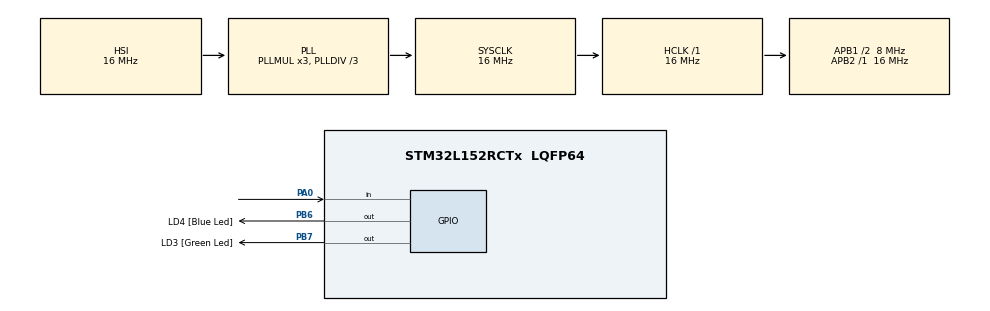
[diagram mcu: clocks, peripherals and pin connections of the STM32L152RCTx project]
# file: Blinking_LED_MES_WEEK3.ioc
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Mcu.Family=STM32L1
Mcu.Name=STM32L152RCTx
Mcu.Package=LQFP64
NVIC.PriorityGroup=NVIC_PRIORITYGROUP_0
PA0-WKUP1.GPIO_PuPd=GPIO_PULLDOWN
PA0-WKUP1.Signal=GPIO_Input
PB6.GPIO_Label=LD4 [Blue Led]
PB6.GPIO_ModeDefaultOutputPP=GPIO_MODE_OUTPUT_PP
PB6.GPIO_PuPd=GPIO_NOPULL
PB6.GPIO_Speed=GPIO_SPEED_FREQ_LOW
PB6.Signal=GPIO_Output
PB7.GPIO_Label=LD3 [Green Led]
PB7.GPIO_ModeDefaultOutputPP=GPIO_MODE_OUTPUT_PP
PB7.GPIO_PuPd=GPIO_PULLDOWN
PB7.GPIO_Speed=GPIO_SPEED_FREQ_LOW
PB7.Signal=GPIO_Output
ProjectManager.HeapSize=0x200
ProjectManager.StackSize=0x400
ProjectManager.TargetToolchain=STM32CubeIDE
RCC.48MHZClocksFreq_Value=24000000
RCC.AHBFreq_Value=16000000
RCC.APB1CLKDivider=RCC_HCLK_DIV2
RCC.APB1Freq_Value=8000000
RCC.APB1TimFreq_Value=16000000
RCC.APB2Freq_Value=16000000
RCC.APB2TimFreq_Value=16000000
RCC.HCLKFreq_Value=16000000
RCC.HSE_VALUE=8000000
RCC.HSI_VALUE=16000000
RCC.LSE_VALUE=32768
RCC.MSI_VALUE=2097000
RCC.PLLDIV=RCC_PLL_DIV3
RCC.RTCClockSelection=RCC_RTCCLKSOURCE_LSI
RCC.RTCClockSelectionVirtual=RCC_RTCCLKSOURCE_LSE
RCC.SYSCLKFreq_VALUE=16000000
RCC.SYSCLKSource=RCC_SYSCLKSOURCE_PLLCLK
RCC.USBOutput=48000000
RCC.VCOOutputFreq_Value=48000000
board=STM32L152C-DISCO

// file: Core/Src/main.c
/* USER CODE BEGIN Header */
/**
  ******************************************************************************
  * @file           : main.c
  * @brief          : Main program body
  ******************************************************************************
  * @attention
  *
  * Copyright (c) 2023 STMicroelectronics.
  * All rights reserved.
  *
  * This software is licensed under terms that can be found in the LICENSE file
  * in the root directory of this software component.
  * If no LICENSE file comes with this software, it is provided AS-IS.
  *
  ******************************************************************************
  */
/* USER CODE END Header */
#include "main.h"

void SystemClock_Config(void);
static void MX_GPIO_Init(void);

int main(void)
{

  /* MCU Configuration--------------------------------------------------------*/

  /* Reset of all peripherals, Initializes the Flash interface and the Systick. */
  HAL_Init();

  /* Configure the system clock */
  SystemClock_Config();

  /* Initialize all configured peripherals */
  MX_GPIO_Init();

  /* Infinite loop */
  /* USER CODE BEGIN WHILE */
  while (1)
  {

	  while(HAL_GPIO_ReadPin(GPIOA, GPIO_PIN_0)){
	  HAL_GPIO_WritePin(GPIOB,GPIO_PIN_6,1);
	  HAL_GPIO_WritePin(GPIOB,GPIO_PIN_7,0);
	  HAL_Delay(500);
	  HAL_GPIO_WritePin(GPIOB, GPIO_PIN_6,0);
	  HAL_GPIO_WritePin(GPIOB, GPIO_PIN_7,1);
	  HAL_Delay(500);}
    /* USER CODE END WHILE */

  }
}

void SystemClock_Config(void)
{
  RCC_OscInitTypeDef RCC_OscInitStruct = {0};
  RCC_ClkInitTypeDef RCC_ClkInitStruct = {0};

  /** Configure the main internal regulator output voltage
  */
  __HAL_PWR_VOLTAGESCALING_CONFIG(PWR_REGULATOR_VOLTAGE_SCALE1);

  /** Initializes the RCC Oscillators according to the specified parameters
  * in the RCC_OscInitTypeDef structure.
  */
  RCC_OscInitStruct.OscillatorType = RCC_OSCILLATORTYPE_HSI;
  RCC_OscInitStruct.HSIState = RCC_HSI_ON;
  RCC_OscInitStruct.HSICalibrationValue = RCC_HSICALIBRATION_DEFAULT;
  RCC_OscInitStruct.PLL.PLLState = RCC_PLL_ON;
  RCC_OscInitStruct.PLL.PLLSource = RCC_PLLSOURCE_HSI;
  RCC_OscInitStruct.PLL.PLLMUL = RCC_PLL_MUL3;
  RCC_OscInitStruct.PLL.PLLDIV = RCC_PLL_DIV3;
  if (HAL_RCC_OscConfig(&RCC_OscInitStruct) != HAL_OK)
  {
    Error_Handler();
  }

  /** Initializes the CPU, AHB and APB buses clocks
  */
  RCC_ClkInitStruct.ClockType = RCC_CLOCKTYPE_HCLK|RCC_CLOCKTYPE_SYSCLK
                              |RCC_CLOCKTYPE_PCLK1|RCC_CLOCKTYPE_PCLK2;
  RCC_ClkInitStruct.SYSCLKSource = RCC_SYSCLKSOURCE_PLLCLK;
  RCC_ClkInitStruct.AHBCLKDivider = RCC_SYSCLK_DIV1;
  RCC_ClkInitStruct.APB1CLKDivider = RCC_HCLK_DIV2;
  RCC_ClkInitStruct.APB2CLKDivider = RCC_HCLK_DIV1;

  if (HAL_RCC_ClockConfig(&RCC_ClkInitStruct, FLASH_LATENCY_0) != HAL_OK)
  {
    Error_Handler();
  }
}

static void MX_GPIO_Init(void)
{
  GPIO_InitTypeDef GPIO_InitStruct = {0};

  /* GPIO Ports Clock Enable */
  __HAL_RCC_GPIOA_CLK_ENABLE();
  __HAL_RCC_GPIOB_CLK_ENABLE();

  /*Configure GPIO pin Output Level */
  HAL_GPIO_WritePin(GPIOB, LD4_Pin|LD3_Pin, GPIO_PIN_RESET);

  /*Configure GPIO pin : PA0 */
  GPIO_InitStruct.Pin = GPIO_PIN_0;
  GPIO_InitStruct.Mode = GPIO_MODE_INPUT;
  GPIO_InitStruct.Pull = GPIO_PULLDOWN;
  HAL_GPIO_Init(GPIOA, &GPIO_InitStruct);

  /*Configure GPIO pin : LD4_Pin */
  GPIO_InitStruct.Pin = LD4_Pin;
  GPIO_InitStruct.Mode = GPIO_MODE_OUTPUT_PP;
  GPIO_InitStruct.Pull = GPIO_NOPULL;
  GPIO_InitStruct.Speed = GPIO_SPEED_FREQ_LOW;
  HAL_GPIO_Init(LD4_GPIO_Port, &GPIO_InitStruct);

  /*Configure GPIO pin : LD3_Pin */
  GPIO_InitStruct.Pin = LD3_Pin;
  GPIO_InitStruct.Mode = GPIO_MODE_OUTPUT_PP;
  GPIO_InitStruct.Pull = GPIO_PULLDOWN;
  GPIO_InitStruct.Speed = GPIO_SPEED_FREQ_LOW;
  HAL_GPIO_Init(LD3_GPIO_Port, &GPIO_InitStruct);

}

void Error_Handler(void)
{
  __disable_irq();
  while (1)
  {
  }
}
